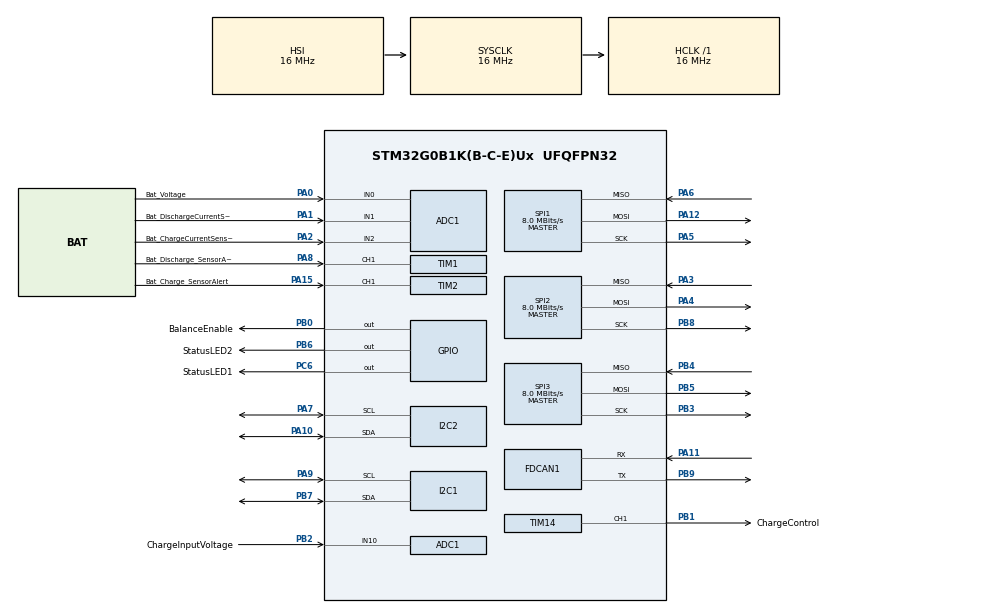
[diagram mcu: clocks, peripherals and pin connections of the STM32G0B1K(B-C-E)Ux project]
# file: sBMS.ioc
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ADC1.Channel-0\#ChannelRegularConversion=ADC_CHANNEL_0
ADC1.NbrOfConversionFlag=1
ADC1.Rank-0\#ChannelRegularConversion=1
ADC1.SamplingTime-0\#ChannelRegularConversion=ADC_SAMPLINGTIME_COMMON_1
ADC1.SelectedChannel=ADC_CHANNEL_0|ADC_CHANNEL_1|ADC_CHANNEL_2|ADC_CHANNEL_TEMPSENSOR|ADC_CHANNEL_10
ADC1.master=1
FDCAN1.CalculateBaudRateNominal=200000
FDCAN1.CalculateTimeBitNominal=5000
FDCAN1.CalculateTimeQuantumNominal=1000.0
FREERTOS.Tasks01=cellMonitor,32,128,StartCellMonitorTask,Default,NULL,Dynamic,NULL,NULL;statusLED,8,128,StartStatusLEDTask,Default,NULL,Dynamic,NULL,NULL;chargeMonitor,40,128,StartChargeMonitorTask,Default,NULL,Dynamic,NULL,NULL;currentMonitor,8,128,StartCurrentMonitorTask,Default,NULL,Dynamic,NULL,NULL;canHandler,16,128,StartCanHandlerTask,Default,NULL,Dynamic,NULL,NULL;cyphalStatus,8,128,StartCyphalStatusTask,Default,NULL,Dynamic,NULL,NULL
FREERTOS.configENABLE_FPU=1
FREERTOS.configTOTAL_HEAP_SIZE=4000
Mcu.Family=STM32G0
Mcu.Name=STM32G0B1K(B-C-E)Ux
Mcu.Package=UFQFPN32
NVIC.TIM17_FDCAN_IT1_IRQn=true\:3\:0\:false\:false\:true\:false\:false\:true\:true
NVIC.TimeBase=TIM17_FDCAN_IT1_IRQn
NVIC.TimeBaseIP=TIM17
PA0.GPIO_Label=Bat_Voltage
PA0.Mode=IN0
PA0.Signal=ADC1_IN0
PA1.GPIO_Label=Bat_DischargeCurrentSensor
PA1.Mode=IN1
PA1.Signal=ADC1_IN1
PA10.Mode=I2C
PA10.Signal=I2C2_SDA
PA11\ [PA9].Mode=FDCAN_Activate
PA11\ [PA9].Signal=FDCAN1_RX
PA12\ [PA10].Mode=Full_Duplex_Master
PA12\ [PA10].Signal=SPI1_MOSI
PA13.Mode=Serial_Wire
PA13.Signal=SYS_SWDIO
PA14-BOOT0.Mode=Serial_Wire
PA14-BOOT0.Signal=SYS_SWCLK
PA15.GPIO_Label=Bat_Charge_SensorAlert
PA15.Signal=S_TIM2_CH1_ETR
PA2.GPIO_Label=Bat_ChargeCurrentSensor
PA2.Mode=IN2
PA2.Signal=ADC1_IN2
PA3.Mode=Full_Duplex_Master
PA3.Signal=SPI2_MISO
PA4.Mode=Full_Duplex_Master
PA4.Signal=SPI2_MOSI
PA5.Mode=Full_Duplex_Master
PA5.Signal=SPI1_SCK
PA6.Mode=Full_Duplex_Master
PA6.Signal=SPI1_MISO
PA7.Mode=I2C
PA7.Signal=I2C2_SCL
PA8.GPIO_Label=Bat_Discharge_SensorAlert
PA8.Signal=S_TIM1_CH1
PA9.Mode=I2C
PA9.Signal=I2C1_SCL
PB0.GPIO_Label=BalanceEnable
PB0.Signal=GPIO_Output
PB1.GPIO_Label=ChargeControl
PB1.Signal=S_TIM14_CH1
PB2.GPIO_Label=ChargeInputVoltage
PB2.Mode=IN10
PB2.Signal=ADC1_IN10
PB3.Mode=Full_Duplex_Master
PB3.Signal=SPI3_SCK
PB4.Mode=Full_Duplex_Master
PB4.Signal=SPI3_MISO
PB5.Mode=Full_Duplex_Master
PB5.Signal=SPI3_MOSI
PB6.GPIO_Label=StatusLED2
PB6.Signal=GPIO_Output
PB7.Mode=I2C
PB7.Signal=I2C1_SDA
PB8.Mode=Full_Duplex_Master
PB8.Signal=SPI2_SCK
PB9.Mode=FDCAN_Activate
PB9.Signal=FDCAN1_TX
PC14-OSC32_IN\ (PC14).Mode=LSE-External-Oscillator
PC14-OSC32_IN\ (PC14).Signal=RCC_OSC32_IN
PC15-OSC32_OUT\ (PC15).Mode=LSE-External-Oscillator
PC15-OSC32_OUT\ (PC15).Signal=RCC_OSC32_OUT
PC6.GPIO_Label=StatusLED1
PC6.Signal=GPIO_Output
ProjectManager.HeapSize=0x200
ProjectManager.StackSize=0x400
ProjectManager.TargetToolchain=Makefile
RCC.ADCFreq_Value=16000000
RCC.AHBFreq_Value=16000000
RCC.CortexFreq_Value=16000000
RCC.EXTERNAL_CLOCK_VALUE=48000
RCC.HCLKFreq_Value=16000000
RCC.HSE_VALUE=8000000
RCC.HSI48_VALUE=48000000
RCC.HSI_VALUE=16000000
RCC.SYSCLKFreq_VALUE=16000000
RCC.USBFreq_Value=48000000
RCC.VCOOutputFreq_Value=128000000
SH.S_TIM14_CH1.0=TIM14_CH1,PWM Generation1 CH1
SH.S_TIM1_CH1.0=TIM1_CH1,PWM_Input_1
SH.S_TIM2_CH1_ETR.0=TIM2_CH1,PWM_Input_1
SPI1.CalculateBaudRate=8.0 MBits/s
SPI1.Direction=SPI_DIRECTION_2LINES
SPI1.Mode=SPI_MODE_MASTER
SPI1.VirtualType=VM_MASTER
SPI2.CalculateBaudRate=8.0 MBits/s
SPI2.Direction=SPI_DIRECTION_2LINES
SPI2.Mode=SPI_MODE_MASTER
SPI2.VirtualType=VM_MASTER
SPI3.CalculateBaudRate=8.0 MBits/s
SPI3.Direction=SPI_DIRECTION_2LINES
SPI3.Mode=SPI_MODE_MASTER
SPI3.VirtualType=VM_MASTER
TIM14.Channel=TIM_CHANNEL_1
VP_ADC1_TempSens_Input.Mode=IN-TempSens
VP_FREERTOS_VS_CMSIS_V2.Mode=CMSIS_V2
VP_RTC_VS_RTC_Activate.Mode=RTC_Enabled
VP_SYS_VS_DBSignals.Mode=DisableDeadBatterySignals
VP_SYS_VS_tim17.Mode=TIM17
VP_TIM14_VS_ClockSourceINT.Mode=Enable_Timer
board=custom

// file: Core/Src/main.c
/* USER CODE BEGIN Header */
/**
  ******************************************************************************
  * @file           : main.c
  * @brief          : Main program body
  ******************************************************************************
  * @attention
  *
  * Copyright (c) 2023 STMicroelectronics.
  * All rights reserved.
  *
  * This software is licensed under terms that can be found in the LICENSE file
  * in the root directory of this software component.
  * If no LICENSE file comes with this software, it is provided AS-IS.
  *
  ******************************************************************************
  */
/* USER CODE END Header */
#include "main.h"
#include "cmsis_os.h"
#include "adc.h"
#include "fdcan.h"
#include "i2c.h"
#include "rtc.h"
#include "spi.h"
#include "tim.h"
#include "gpio.h"

void SystemClock_Config(void);
void MX_FREERTOS_Init(void);

int main(void)
{

  /* MCU Configuration--------------------------------------------------------*/

  /* Reset of all peripherals, Initializes the Flash interface and the Systick. */
  HAL_Init();

  /* Configure the system clock */
  SystemClock_Config();

  /* Initialize all configured peripherals */
  MX_GPIO_Init();
  MX_ADC1_Init();
  MX_FDCAN1_Init();
  MX_I2C1_Init();
  MX_I2C2_Init();
  MX_SPI1_Init();
  MX_SPI2_Init();
  MX_SPI3_Init();
  MX_TIM1_Init();
  MX_TIM2_Init();
  MX_RTC_Init();
  MX_TIM14_Init();

  /* Init scheduler */
  osKernelInitialize();  /* Call init function for freertos objects (in freertos.c) */
  MX_FREERTOS_Init();

  /* Start scheduler */
  osKernelStart();

  /* We should never get here as control is now taken by the scheduler */
  /* Infinite loop */
  while (1)
  {

  }
}

void SystemClock_Config(void)
{
  RCC_OscInitTypeDef RCC_OscInitStruct = {0};
  RCC_ClkInitTypeDef RCC_ClkInitStruct = {0};

  /** Configure the main internal regulator output voltage
  */
  HAL_PWREx_ControlVoltageScaling(PWR_REGULATOR_VOLTAGE_SCALE1);

  /** Initializes the RCC Oscillators according to the specified parameters
  * in the RCC_OscInitTypeDef structure.
  */
  RCC_OscInitStruct.OscillatorType = RCC_OSCILLATORTYPE_HSI|RCC_OSCILLATORTYPE_LSI;
  RCC_OscInitStruct.HSIState = RCC_HSI_ON;
  RCC_OscInitStruct.HSIDiv = RCC_HSI_DIV1;
  RCC_OscInitStruct.HSICalibrationValue = RCC_HSICALIBRATION_DEFAULT;
  RCC_OscInitStruct.LSIState = RCC_LSI_ON;
  RCC_OscInitStruct.PLL.PLLState = RCC_PLL_NONE;
  if (HAL_RCC_OscConfig(&RCC_OscInitStruct) != HAL_OK)
  {
    Error_Handler();
  }

  /** Initializes the CPU, AHB and APB buses clocks
  */
  RCC_ClkInitStruct.ClockType = RCC_CLOCKTYPE_HCLK|RCC_CLOCKTYPE_SYSCLK
                              |RCC_CLOCKTYPE_PCLK1;
  RCC_ClkInitStruct.SYSCLKSource = RCC_SYSCLKSOURCE_HSI;
  RCC_ClkInitStruct.AHBCLKDivider = RCC_SYSCLK_DIV1;
  RCC_ClkInitStruct.APB1CLKDivider = RCC_HCLK_DIV1;

  if (HAL_RCC_ClockConfig(&RCC_ClkInitStruct, FLASH_LATENCY_0) != HAL_OK)
  {
    Error_Handler();
  }
}

void HAL_TIM_PeriodElapsedCallback(TIM_HandleTypeDef *htim)
{
  if (htim->Instance == TIM17) {
    HAL_IncTick();
  }
}

void Error_Handler(void)
{
  __disable_irq();
  while (1)
  {
  }
}

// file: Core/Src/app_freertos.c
/* USER CODE BEGIN Header */
/**
  ******************************************************************************
  * File Name          : app_freertos.c
  * Description        : Code for freertos applications
  ******************************************************************************
  * @attention
  *
  * Copyright (c) 2023 STMicroelectronics.
  * All rights reserved.
  *
  * This software is licensed under terms that can be found in the LICENSE file
  * in the root directory of this software component.
  * If no LICENSE file comes with this software, it is provided AS-IS.
  *
  ******************************************************************************
  */
/* USER CODE END Header */

#include "FreeRTOS.h"
#include "task.h"
#include "main.h"
#include "cmsis_os.h"

/* USER CODE BEGIN Includes */
#include "tasks.h"
/* USER CODE END Includes */

/* Definitions for cellMonitor */
osThreadId_t cellMonitorHandle;
const osThreadAttr_t cellMonitor_attributes = {
  .name = "cellMonitor",
  .priority = (osPriority_t) osPriorityAboveNormal,
  .stack_size = 128 * 4
};
/* Definitions for statusLED */
osThreadId_t statusLEDHandle;
const osThreadAttr_t statusLED_attributes = {
  .name = "statusLED",
  .priority = (osPriority_t) osPriorityLow,
  .stack_size = 128 * 4
};
/* Definitions for chargeMonitor */
osThreadId_t chargeMonitorHandle;
const osThreadAttr_t chargeMonitor_attributes = {
  .name = "chargeMonitor",
  .priority = (osPriority_t) osPriorityHigh,
  .stack_size = 128 * 4
};
/* Definitions for currentMonitor */
osThreadId_t currentMonitorHandle;
const osThreadAttr_t currentMonitor_attributes = {
  .name = "currentMonitor",
  .priority = (osPriority_t) osPriorityLow,
  .stack_size = 128 * 4
};
/* Definitions for canHandler */
osThreadId_t canHandlerHandle;
const osThreadAttr_t canHandler_attributes = {
  .name = "canHandler",
  .priority = (osPriority_t) osPriorityBelowNormal,
  .stack_size = 128 * 4
};
/* Definitions for cyphalStatus */
osThreadId_t cyphalStatusHandle;
const osThreadAttr_t cyphalStatus_attributes = {
  .name = "cyphalStatus",
  .priority = (osPriority_t) osPriorityLow,
  .stack_size = 128 * 4
};

void StartCellMonitorTask(void *argument);
void StartStatusLEDTask(void *argument);
void StartChargeMonitorTask(void *argument);
void StartCurrentMonitorTask(void *argument);
void StartCanHandlerTask(void *argument);
void StartCyphalStatusTask(void *argument);

void MX_FREERTOS_Init(void); /* (MISRA C 2004 rule 8.1) */

void MX_FREERTOS_Init(void) {

  /* Create the thread(s) */
  /* creation of cellMonitor */
  cellMonitorHandle = osThreadNew(StartCellMonitorTask, NULL, &cellMonitor_attributes);

  /* creation of statusLED */
  statusLEDHandle = osThreadNew(StartStatusLEDTask, NULL, &statusLED_attributes);

  /* creation of chargeMonitor */
  chargeMonitorHandle = osThreadNew(StartChargeMonitorTask, NULL, &chargeMonitor_attributes);

  /* creation of currentMonitor */
  currentMonitorHandle = osThreadNew(StartCurrentMonitorTask, NULL, &currentMonitor_attributes);

  /* creation of canHandler */
  canHandlerHandle = osThreadNew(StartCanHandlerTask, NULL, &canHandler_attributes);

  /* creation of cyphalStatus */
  cyphalStatusHandle = osThreadNew(StartCyphalStatusTask, NULL, &cyphalStatus_attributes);

}

void StartCellMonitorTask(void *argument)
{
  /* USER CODE BEGIN StartCellMonitorTask */
  cellMonitorTask();
  /* USER CODE END StartCellMonitorTask */
}

void StartStatusLEDTask(void *argument)
{
  for(;;)
  {
    osDelay(1);
  }
}

void StartChargeMonitorTask(void *argument)
{
  for(;;)
  {
    osDelay(1);
  }
}

void StartCurrentMonitorTask(void *argument)
{
  for(;;)
  {
    osDelay(1);
  }
}

void StartCanHandlerTask(void *argument)
{
  for(;;)
  {
    osDelay(1);
  }
}

void StartCyphalStatusTask(void *argument)
{
  for(;;)
  {
    osDelay(1);
  }
}
